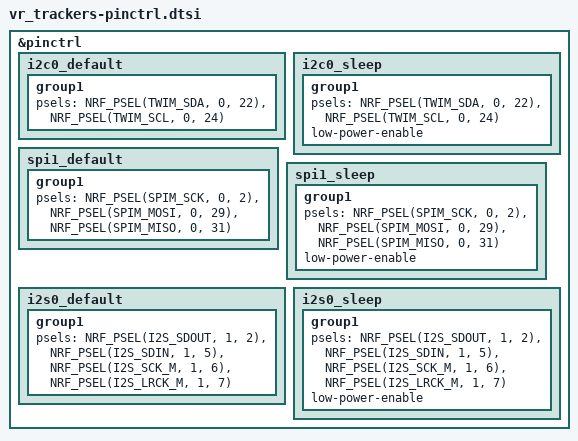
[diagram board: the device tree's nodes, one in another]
&pinctrl {
	i2c0_default: i2c0_default {
		group1 {
			psels = <NRF_PSEL(TWIM_SDA, 0, 22)>,
				<NRF_PSEL(TWIM_SCL, 0, 24)>;
		};
	};

	i2c0_sleep: i2c0_sleep {
		group1 {
			psels = <NRF_PSEL(TWIM_SDA, 0, 22)>,
				<NRF_PSEL(TWIM_SCL, 0, 24)>;
			low-power-enable;
		};
	};

	spi1_default: spi1_default {
		group1 {
			psels = <NRF_PSEL(SPIM_SCK, 0, 2)>,
				<NRF_PSEL(SPIM_MOSI, 0, 29)>,
				<NRF_PSEL(SPIM_MISO, 0, 31)>;
		};
	};

	spi1_sleep: spi1_sleep {
		group1 {
			psels = <NRF_PSEL(SPIM_SCK, 0, 2)>,
				<NRF_PSEL(SPIM_MOSI, 0, 29)>,
				<NRF_PSEL(SPIM_MISO, 0, 31)>;
			low-power-enable;
		};
	};

	i2s0_default: i2s0_default {
		group1 {
				// there are unused pins because im using ws2812 over i2s with a
				// trick to only use the SDOUT line, but they still need to 
				// be configured for the peripheral to work
			psels = <NRF_PSEL(I2S_SDOUT, 1, 2)>,
				<NRF_PSEL(I2S_SDIN, 1, 5)>,
				<NRF_PSEL(I2S_SCK_M, 1, 6)>,
				<NRF_PSEL(I2S_LRCK_M, 1, 7)>;
		};
	};

	i2s0_sleep: i2s0_sleep {
		group1 {
			psels = <NRF_PSEL(I2S_SDOUT, 1, 2)>,
				<NRF_PSEL(I2S_SDIN, 1, 5)>,
				<NRF_PSEL(I2S_SCK_M, 1, 6)>,
				<NRF_PSEL(I2S_LRCK_M, 1, 7)>;
			low-power-enable;
		};
	};
};
